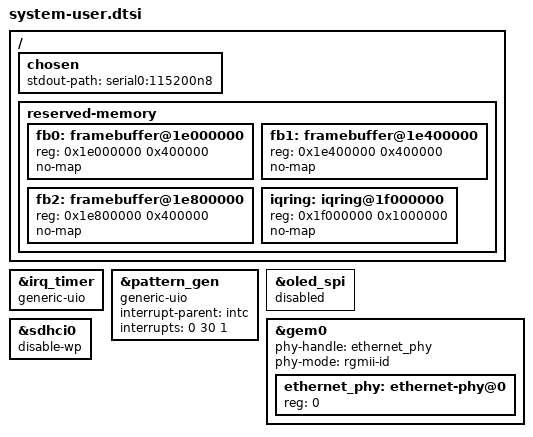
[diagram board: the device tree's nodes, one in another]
/include/ "system-conf.dtsi"
/*
 * ZedBoard – benutzerspezifische Device-Tree-Ergaenzungen
 * Ziel: project-spec/meta-user/recipes-bsp/device-tree/files/system-user.dtsi
 */
/ {
	chosen {
		stdout-path = "serial0:115200n8";
	};

	/*
	 * Drei Framebuffer fuer den HDMI-Testbild-Generator (1920x1080, 2 Byte pro Pixel
	 * = 4147200 Byte, je 4 MiB reserviert). Linux nutzt diesen Speicher nicht; der
	 * Core liest ihn ueber den HP0-Port, fb_test beschreibt ihn ueber /dev/mem.
	 */
	reserved-memory {
		#address-cells = <1>;
		#size-cells = <1>;
		ranges;

		fb0: framebuffer@1e000000 {
			reg = <0x1e000000 0x400000>;
			no-map;
		};
		fb1: framebuffer@1e400000 {
			reg = <0x1e400000 0x400000>;
			no-map;
		};
		fb2: framebuffer@1e800000 {
			reg = <0x1e800000 0x400000>;
			no-map;
		};
		/*
		 * Ringpuffer fuer I/Q-Daten vom HackRF auf dem Weg in die PL (16 MiB, etwa
		 * 0,5 s bei 16 Msps): iq_rx schreibt ueber /dev/mem, der Core iq_reader
		 * liest ueber den HP1-Port.
		 */
		iqring: iqring@1f000000 {
			reg = <0x1f000000 0x1000000>;
			no-map;
		};
	};
};

/*
 * Messung der Interrupt-Laufzeit (rtl/irq_timer.v): der Knoten kommt mit Adresse und
 * Interrupt aus der Hardware-Beschreibung. Mit diesem Namen uebernimmt ihn der Treiber
 * uio_pdrv_genirq (modprobe uio_pdrv_genirq of_id=generic-uio), irq_test bedient ihn
 * dann ueber /dev/uioN.
 */
&irq_timer {
	compatible = "generic-uio";
};

/*
 * Testbild-Generator (hls/pattern_gen.cpp): als UIO-Geraet mit dem Puls am Bildanfang
 * (IRQ_F2P[1] = SPI 62, steigende Flanke), damit vec_demo die Linientabelle bildgenau
 * nachfuehren kann. Der Interrupt steht nicht in der Hardware-Beschreibung, weil der
 * HLS-Ausgang frame_irq dort kein Interrupt-Anschluss ist.
 */
&pattern_gen {
	compatible = "generic-uio";
	interrupt-parent = <&intc>;
	interrupts = <0 30 1>;
};

/*
 * OLED-Anzeige: den SPI-Core bedienen oled und irq_test selbst ueber /dev/mem (target/oled.h),
 * der Kernel-Treiber soll ihn nicht belegen.
 */
&oled_spi {
	status = "disabled";
};

/* Ethernet: Marvell 88E1518 PHY auf MDIO-Adresse 0 */
&gem0 {
	phy-handle = <&ethernet_phy>;
	phy-mode = "rgmii-id";
	ethernet_phy: ethernet-phy@0 {
		reg = <0>;
		device_type = "ethernet-phy";
	};
};

/* SD-Karte: kein Card-Detect-Problem, Karte ist beim Boot vorhanden */
&sdhci0 {
	disable-wp;
};

/*
 * USB-OTG (J13): laeuft bereits als Host (dr_mode = "host" kommt aus den
 * ZedBoard-Teilen von PetaLinux), hier ist dafuer nichts einzutragen.
 */
